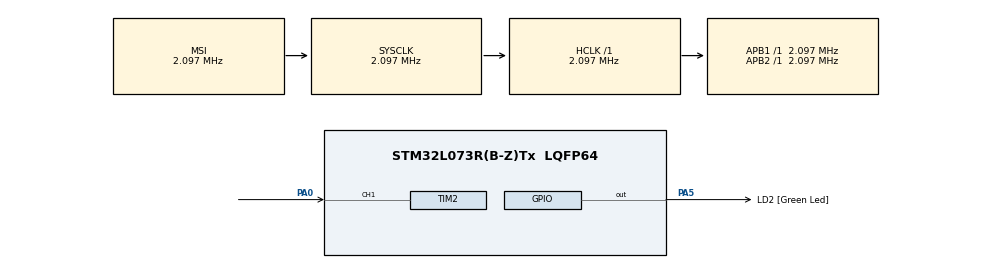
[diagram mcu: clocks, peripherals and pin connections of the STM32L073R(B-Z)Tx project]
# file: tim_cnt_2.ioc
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Mcu.Family=STM32L0
Mcu.Name=STM32L073R(B-Z)Tx
Mcu.Package=LQFP64
PA0.GPIO_Speed=GPIO_SPEED_FREQ_HIGH
PA0.Signal=S_TIM2_CH1
PA13.GPIO_Label=TMS
PA13.Signal=SYS_SWDIO
PA14.GPIO_Label=TCK
PA14.Signal=SYS_SWCLK
PA5.GPIO_Label=LD2 [Green Led]
PA5.Signal=GPIO_Output
PC14-OSC32_IN.Signal=RCC_OSC32_IN
PC15-OSC32_OUT.Signal=RCC_OSC32_OUT
PH0-OSC_IN.GPIO_Label=MCO
PH0-OSC_IN.Signal=RCC_OSC_IN
ProjectManager.HeapSize=0x200
ProjectManager.StackSize=0x400
ProjectManager.TargetToolchain=SW4STM32
RCC.AHBFreq_Value=2097000
RCC.APB1Freq_Value=2097000
RCC.APB1TimFreq_Value=2097000
RCC.APB2Freq_Value=2097000
RCC.APB2TimFreq_Value=2097000
RCC.HSE_VALUE=8000000
RCC.HSI16_VALUE=16000000
RCC.HSI48_VALUE=48000000
RCC.HSI_VALUE=16000000
RCC.LSEState=RCC_LSE_ON
RCC.LSE_VALUE=32768
RCC.MSI_VALUE=2097000
RCC.SYSCLKFreq_VALUE=2097000
RCC.VCOOutputFreq_Value=48000000
SH.S_TIM2_CH1.0=TIM2_CH1,TriggerSource_TI1FP1
TIM2.Period=1000
TIM2.Slave_TriggerFilter=15
TIM2.Slave_TriggerPolarity=TIM_TRIGGERPOLARITY_FALLING
TIM2.TIM_MasterOutputTrigger=TIM_TRGO_RESET
TIM2.TIM_MasterSlaveMode=TIM_MASTERSLAVEMODE_ENABLE
VP_TIM2_VS_ControllerModeClock.Mode=Clock Mode
board=NUCLEO-L073RZ

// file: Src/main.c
/**
  ******************************************************************************
  * File Name          : main.c
  * Description        : Main program body
  ******************************************************************************
  ** This notice applies to any and all portions of this file
  * that are not between comment pairs USER CODE BEGIN and
  * USER CODE END. Other portions of this file, whether
  * inserted by the user or by software development tools
  * are owned by their respective copyright owners.
  *
  * COPYRIGHT(c) 2018 STMicroelectronics
  *
  * Redistribution and use in source and binary forms, with or without modification,
  * are permitted provided that the following conditions are met:
  *   1. Redistributions of source code must retain the above copyright notice,
  *      this list of conditions and the following disclaimer.
  *   2. Redistributions in binary form must reproduce the above copyright notice,
  *      this list of conditions and the following disclaimer in the documentation
  *      and/or other materials provided with the distribution.
  *   3. Neither the name of STMicroelectronics nor the names of its contributors
  *      may be used to endorse or promote products derived from this software
  *      without specific prior written permission.
  *
  * THIS SOFTWARE IS PROVIDED BY THE COPYRIGHT HOLDERS AND CONTRIBUTORS "AS IS"
  * AND ANY EXPRESS OR IMPLIED WARRANTIES, INCLUDING, BUT NOT LIMITED TO, THE
  * IMPLIED WARRANTIES OF MERCHANTABILITY AND FITNESS FOR A PARTICULAR PURPOSE ARE
  * DISCLAIMED. IN NO EVENT SHALL THE COPYRIGHT HOLDER OR CONTRIBUTORS BE LIABLE
  * FOR ANY DIRECT, INDIRECT, INCIDENTAL, SPECIAL, EXEMPLARY, OR CONSEQUENTIAL
  * DAMAGES (INCLUDING, BUT NOT LIMITED TO, PROCUREMENT OF SUBSTITUTE GOODS OR
  * SERVICES; LOSS OF USE, DATA, OR PROFITS; OR BUSINESS INTERRUPTION) HOWEVER
  * CAUSED AND ON ANY THEORY OF LIABILITY, WHETHER IN CONTRACT, STRICT LIABILITY,
  * OR TORT (INCLUDING NEGLIGENCE OR OTHERWISE) ARISING IN ANY WAY OUT OF THE USE
  * OF THIS SOFTWARE, EVEN IF ADVISED OF THE POSSIBILITY OF SUCH DAMAGE.
  *
  ******************************************************************************
  */
#include "main.h"
#include "stm32l0xx_hal.h"

TIM_HandleTypeDef htim2;

/* USER CODE BEGIN PV */
/* Private variables ---------------------------------------------------------*/

/* USER CODE END PV */

void SystemClock_Config(void);
static void MX_GPIO_Init(void);
static void MX_TIM2_Init(void);
volatile uint32_t count1;
/* USER CODE BEGIN PFP */
/* Private function prototypes -----------------------------------------------*/

/* USER CODE END PFP */

int main(void)
{

  /* MCU Configuration----------------------------------------------------------*/

  /* Reset of all peripherals, Initializes the Flash interface and the Systick. */
  HAL_Init();

  /* Configure the system clock */
  SystemClock_Config();

  /* Initialize all configured peripherals */
  MX_GPIO_Init();
  MX_TIM2_Init();

  /* USER CODE BEGIN 2 */
  HAL_TIM_Base_Start(&htim2);
  /* USER CODE END 2 */

  /* Infinite loop */
  /* USER CODE BEGIN WHILE */
  while (1)
  {

	  count1=TIM2->CNT;
  /* USER CODE END WHILE */
	  if(count1==10)
__HAL_TIM_SET_COUNTER(&htim2,0);
  }

}

/** System Clock Configuration
*/
void SystemClock_Config(void)
{

  RCC_OscInitTypeDef RCC_OscInitStruct;
  RCC_ClkInitTypeDef RCC_ClkInitStruct;

    /**Configure the main internal regulator output voltage
    */
  __HAL_PWR_VOLTAGESCALING_CONFIG(PWR_REGULATOR_VOLTAGE_SCALE1);

    /**Initializes the CPU, AHB and APB busses clocks
    */
  RCC_OscInitStruct.OscillatorType = RCC_OSCILLATORTYPE_MSI;
  RCC_OscInitStruct.MSIState = RCC_MSI_ON;
  RCC_OscInitStruct.MSICalibrationValue = 0;
  RCC_OscInitStruct.MSIClockRange = RCC_MSIRANGE_5;
  RCC_OscInitStruct.PLL.PLLState = RCC_PLL_NONE;
  if (HAL_RCC_OscConfig(&RCC_OscInitStruct) != HAL_OK)
  {
    _Error_Handler(__FILE__, __LINE__);
  }

    /**Initializes the CPU, AHB and APB busses clocks
    */
  RCC_ClkInitStruct.ClockType = RCC_CLOCKTYPE_HCLK|RCC_CLOCKTYPE_SYSCLK
                              |RCC_CLOCKTYPE_PCLK1|RCC_CLOCKTYPE_PCLK2;
  RCC_ClkInitStruct.SYSCLKSource = RCC_SYSCLKSOURCE_MSI;
  RCC_ClkInitStruct.AHBCLKDivider = RCC_SYSCLK_DIV1;
  RCC_ClkInitStruct.APB1CLKDivider = RCC_HCLK_DIV1;
  RCC_ClkInitStruct.APB2CLKDivider = RCC_HCLK_DIV1;

  if (HAL_RCC_ClockConfig(&RCC_ClkInitStruct, FLASH_LATENCY_0) != HAL_OK)
  {
    _Error_Handler(__FILE__, __LINE__);
  }

    /**Configure the Systick interrupt time
    */
  HAL_SYSTICK_Config(HAL_RCC_GetHCLKFreq()/1000);

    /**Configure the Systick
    */
  HAL_SYSTICK_CLKSourceConfig(SYSTICK_CLKSOURCE_HCLK);

  /* SysTick_IRQn interrupt configuration */
  HAL_NVIC_SetPriority(SysTick_IRQn, 0, 0);
}

/* TIM2 init function */
static void MX_TIM2_Init(void)
{

  TIM_SlaveConfigTypeDef sSlaveConfig;
  TIM_MasterConfigTypeDef sMasterConfig;

  htim2.Instance = TIM2;
  htim2.Init.Prescaler = 0;
  htim2.Init.CounterMode = TIM_COUNTERMODE_UP;
  htim2.Init.Period = 1000;
  htim2.Init.ClockDivision = TIM_CLOCKDIVISION_DIV1;
  if (HAL_TIM_Base_Init(&htim2) != HAL_OK)
  {
    _Error_Handler(__FILE__, __LINE__);
  }

  sSlaveConfig.SlaveMode = TIM_SLAVEMODE_EXTERNAL1;
  sSlaveConfig.InputTrigger = TIM_TS_TI1FP1;
  sSlaveConfig.TriggerPolarity = TIM_TRIGGERPOLARITY_FALLING;
  sSlaveConfig.TriggerFilter = 15;
  if (HAL_TIM_SlaveConfigSynchronization(&htim2, &sSlaveConfig) != HAL_OK)
  {
    _Error_Handler(__FILE__, __LINE__);
  }

  sMasterConfig.MasterOutputTrigger = TIM_TRGO_RESET;
  sMasterConfig.MasterSlaveMode = TIM_MASTERSLAVEMODE_ENABLE;
  if (HAL_TIMEx_MasterConfigSynchronization(&htim2, &sMasterConfig) != HAL_OK)
  {
    _Error_Handler(__FILE__, __LINE__);
  }

}

/** Configure pins as
        * Analog
        * Input
        * Output
        * EVENT_OUT
        * EXTI
*/
static void MX_GPIO_Init(void)
{

  GPIO_InitTypeDef GPIO_InitStruct;

  /* GPIO Ports Clock Enable */
  __HAL_RCC_GPIOC_CLK_ENABLE();
  __HAL_RCC_GPIOH_CLK_ENABLE();
  __HAL_RCC_GPIOA_CLK_ENABLE();

  /*Configure GPIO pin Output Level */
  HAL_GPIO_WritePin(LD2_GPIO_Port, LD2_Pin, GPIO_PIN_RESET);

  /*Configure GPIO pin : LD2_Pin */
  GPIO_InitStruct.Pin = LD2_Pin;
  GPIO_InitStruct.Mode = GPIO_MODE_OUTPUT_PP;
  GPIO_InitStruct.Pull = GPIO_NOPULL;
  GPIO_InitStruct.Speed = GPIO_SPEED_FREQ_LOW;
  HAL_GPIO_Init(LD2_GPIO_Port, &GPIO_InitStruct);

}

void _Error_Handler(char * file, int line)
{
  while(1)
  {
  }
}

/************************ (C) COPYRIGHT STMicroelectronics *****END OF FILE****/
